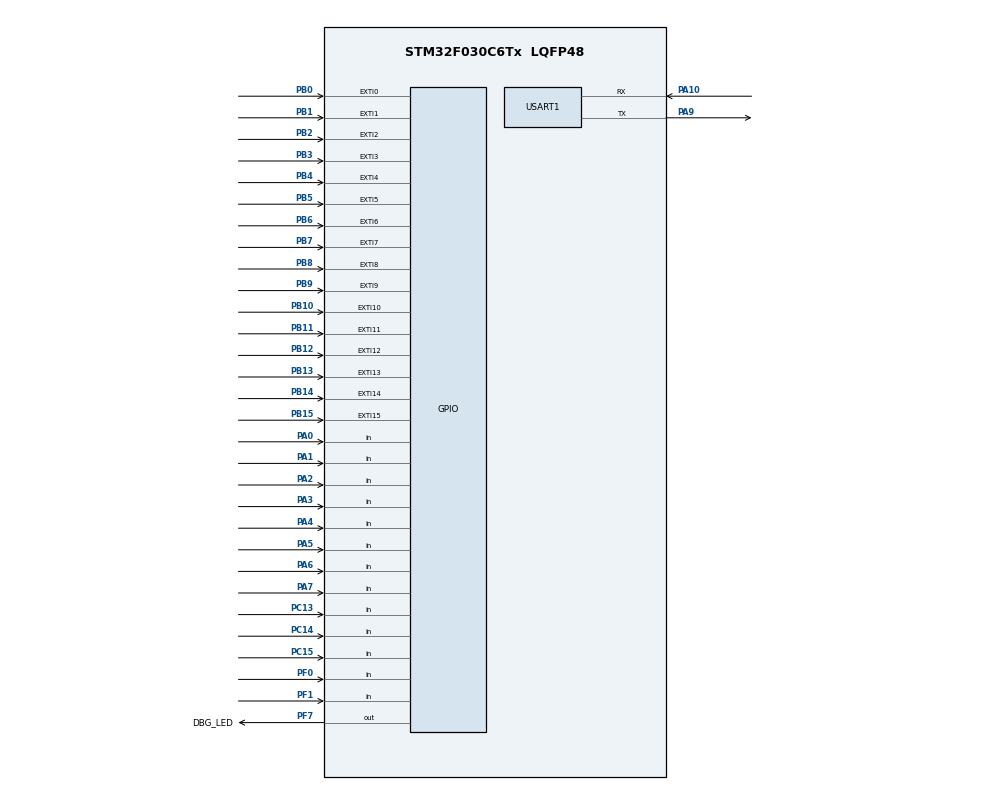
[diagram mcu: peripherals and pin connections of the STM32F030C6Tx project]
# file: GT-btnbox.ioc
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Mcu.Family=STM32F0
Mcu.Name=STM32F030C6Tx
Mcu.Package=LQFP48
NVIC.EXTI0_1_IRQn=true\:2\:0\:true\:true\:true\:1\:true
NVIC.EXTI2_3_IRQn=true\:2\:0\:true\:true\:true\:2\:true
NVIC.EXTI4_15_IRQn=true\:2\:0\:true\:true\:true\:3\:true
PA0.GPIO_PuPd=GPIO_PULLUP
PA0.Signal=GPIO_Input
PA1.GPIO_PuPd=GPIO_PULLUP
PA1.Signal=GPIO_Input
PA10.Mode=Asynchronous
PA10.Signal=USART1_RX
PA13.Mode=Serial_Wire
PA13.Signal=SYS_SWDIO
PA14.Mode=Serial_Wire
PA14.Signal=SYS_SWCLK
PA2.GPIO_PuPd=GPIO_PULLUP
PA2.Signal=GPIO_Input
PA3.GPIO_PuPd=GPIO_PULLUP
PA3.Signal=GPIO_Input
PA4.GPIO_PuPd=GPIO_PULLUP
PA4.Signal=GPIO_Input
PA5.GPIO_PuPd=GPIO_PULLUP
PA5.Signal=GPIO_Input
PA6.GPIO_PuPd=GPIO_PULLUP
PA6.Signal=GPIO_Input
PA7.GPIO_PuPd=GPIO_PULLUP
PA7.Signal=GPIO_Input
PA8.GPIO_Speed=GPIO_SPEED_FREQ_HIGH
PA8.Signal=S_TIM1_CH1
PA9.Mode=Asynchronous
PA9.Signal=USART1_TX
PB0.GPIO_PuPd=GPIO_PULLUP
PB0.Signal=GPXTI0
PB1.GPIO_PuPd=GPIO_PULLUP
PB1.Signal=GPXTI1
PB10.GPIO_PuPd=GPIO_PULLUP
PB10.Signal=GPXTI10
PB11.GPIO_PuPd=GPIO_PULLUP
PB11.Signal=GPXTI11
PB12.GPIO_PuPd=GPIO_PULLUP
PB12.Signal=GPXTI12
PB13.GPIO_PuPd=GPIO_PULLUP
PB13.Signal=GPXTI13
PB14.GPIO_PuPd=GPIO_PULLUP
PB14.Signal=GPXTI14
PB15.GPIO_PuPd=GPIO_PULLUP
PB15.Signal=GPXTI15
PB2.GPIO_PuPd=GPIO_PULLUP
PB2.Signal=GPXTI2
PB3.GPIO_PuPd=GPIO_PULLUP
PB3.Signal=GPXTI3
PB4.GPIO_PuPd=GPIO_PULLUP
PB4.Signal=GPXTI4
PB5.GPIO_PuPd=GPIO_PULLUP
PB5.Signal=GPXTI5
PB6.GPIO_PuPd=GPIO_PULLUP
PB6.Signal=GPXTI6
PB7.GPIO_PuPd=GPIO_PULLUP
PB7.Signal=GPXTI7
PB8.GPIO_PuPd=GPIO_PULLUP
PB8.Signal=GPXTI8
PB9.GPIO_PuPd=GPIO_PULLUP
PB9.Signal=GPXTI9
PC13.GPIO_PuPd=GPIO_PULLUP
PC13.Signal=GPIO_Input
PC14-OSC32_IN.GPIO_PuPd=GPIO_PULLUP
PC14-OSC32_IN.Signal=GPIO_Input
PC15-OSC32_OUT.GPIO_PuPd=GPIO_PULLUP
PC15-OSC32_OUT.Signal=GPIO_Input
PF0-OSC_IN.GPIO_PuPd=GPIO_PULLUP
PF0-OSC_IN.Signal=GPIO_Input
PF1-OSC_OUT.GPIO_PuPd=GPIO_PULLUP
PF1-OSC_OUT.Signal=GPIO_Input
PF7.GPIO_Label=DBG_LED
PF7.GPIO_PuPd=GPIO_NOPULL
PF7.Signal=GPIO_Output
ProjectManager.HeapSize=0x200
ProjectManager.StackSize=0x400
ProjectManager.TargetToolchain=MDK-ARM V5
SH.S_TIM1_CH1.0=TIM1_CH1
USART1.VirtualMode-Asynchronous=VM_ASYNC
board=custom

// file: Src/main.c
/**
  ******************************************************************************
  * @file           : main.c
  * @brief          : Main program body
  ******************************************************************************
  ** This notice applies to any and all portions of this file
  * that are not between comment pairs USER CODE BEGIN and
  * USER CODE END. Other portions of this file, whether
  * inserted by the user or by software development tools
  * are owned by their respective copyright owners.
  *
  * COPYRIGHT(c) 2018 STMicroelectronics
  *
  * Redistribution and use in source and binary forms, with or without modification,
  * are permitted provided that the following conditions are met:
  *   1. Redistributions of source code must retain the above copyright notice,
  *      this list of conditions and the following disclaimer.
  *   2. Redistributions in binary form must reproduce the above copyright notice,
  *      this list of conditions and the following disclaimer in the documentation
  *      and/or other materials provided with the distribution.
  *   3. Neither the name of STMicroelectronics nor the names of its contributors
  *      may be used to endorse or promote products derived from this software
  *      without specific prior written permission.
  *
  * THIS SOFTWARE IS PROVIDED BY THE COPYRIGHT HOLDERS AND CONTRIBUTORS "AS IS"
  * AND ANY EXPRESS OR IMPLIED WARRANTIES, INCLUDING, BUT NOT LIMITED TO, THE
  * IMPLIED WARRANTIES OF MERCHANTABILITY AND FITNESS FOR A PARTICULAR PURPOSE ARE
  * DISCLAIMED. IN NO EVENT SHALL THE COPYRIGHT HOLDER OR CONTRIBUTORS BE LIABLE
  * FOR ANY DIRECT, INDIRECT, INCIDENTAL, SPECIAL, EXEMPLARY, OR CONSEQUENTIAL
  * DAMAGES (INCLUDING, BUT NOT LIMITED TO, PROCUREMENT OF SUBSTITUTE GOODS OR
  * SERVICES; LOSS OF USE, DATA, OR PROFITS; OR BUSINESS INTERRUPTION) HOWEVER
  * CAUSED AND ON ANY THEORY OF LIABILITY, WHETHER IN CONTRACT, STRICT LIABILITY,
  * OR TORT (INCLUDING NEGLIGENCE OR OTHERWISE) ARISING IN ANY WAY OUT OF THE USE
  * OF THIS SOFTWARE, EVEN IF ADVISED OF THE POSSIBILITY OF SUCH DAMAGE.
  *
  ******************************************************************************
  */
#include "main.h"
#include "stm32f0xx_hal.h"
#include "usart.h"
#include "gpio.h"

/* USER CODE BEGIN PV */
/* Private variables ---------------------------------------------------------*/

/* USER CODE END PV */

void SystemClock_Config(void);
static void MX_NVIC_Init(void);

/* USER CODE BEGIN PFP */
/* Private function prototypes -----------------------------------------------*/

/* USER CODE END PFP */

/* USER CODE BEGIN 0 */

//http://www.rotr.info/electronics/mcu/stm32f100/stm32_exti.htm

/* USER CODE END 0 */

int main(void)
{

  /* MCU Configuration----------------------------------------------------------*/

  /* Reset of all peripherals, Initializes the Flash interface and the Systick. */
  HAL_Init();

  /* Configure the system clock */
  SystemClock_Config();

  /* Initialize all configured peripherals */
  MX_GPIO_Init();
  MX_USART1_UART_Init();

  /* Initialize interrupts */
  MX_NVIC_Init();
  /* USER CODE BEGIN 2 */

	HAL_NVIC_SetPriority(SysTick_IRQn, 0, 0);

  __WFI();
  __WFI();
  //LL_LPM_EnableSleep();

  /* USER CODE END 2 */

  /* Infinite loop */
  /* USER CODE BEGIN WHILE */
  while (1)
  {
		//Test
		/*
		HAL_Delay(500);
		HAL_GPIO_WritePin(DbgLed_GPIO_Port, DBG_LED, GPIO_PIN_SET);
		HAL_Delay(500);
		HAL_GPIO_WritePin(DbgLed_GPIO_Port, DBG_LED, GPIO_PIN_RESET);
		*/
  /* USER CODE END WHILE */

  }

}

void SystemClock_Config(void)
{

  RCC_OscInitTypeDef RCC_OscInitStruct;
  RCC_ClkInitTypeDef RCC_ClkInitStruct;
  RCC_PeriphCLKInitTypeDef PeriphClkInit;

    /**Initializes the CPU, AHB and APB busses clocks
    */
  RCC_OscInitStruct.OscillatorType = RCC_OSCILLATORTYPE_HSI;
  RCC_OscInitStruct.HSIState = RCC_HSI_ON;
  RCC_OscInitStruct.HSICalibrationValue = 16;
  RCC_OscInitStruct.PLL.PLLState = RCC_PLL_NONE;
  if (HAL_RCC_OscConfig(&RCC_OscInitStruct) != HAL_OK)
  {
    _Error_Handler(__FILE__, __LINE__);
  }

    /**Initializes the CPU, AHB and APB busses clocks
    */
  RCC_ClkInitStruct.ClockType = RCC_CLOCKTYPE_HCLK|RCC_CLOCKTYPE_SYSCLK
                              |RCC_CLOCKTYPE_PCLK1;
  RCC_ClkInitStruct.SYSCLKSource = RCC_SYSCLKSOURCE_HSI;
  RCC_ClkInitStruct.AHBCLKDivider = RCC_SYSCLK_DIV1;
  RCC_ClkInitStruct.APB1CLKDivider = RCC_HCLK_DIV1;

  if (HAL_RCC_ClockConfig(&RCC_ClkInitStruct, FLASH_LATENCY_0) != HAL_OK)
  {
    _Error_Handler(__FILE__, __LINE__);
  }

  PeriphClkInit.PeriphClockSelection = RCC_PERIPHCLK_USART1;
  PeriphClkInit.Usart1ClockSelection = RCC_USART1CLKSOURCE_PCLK1;
  if (HAL_RCCEx_PeriphCLKConfig(&PeriphClkInit) != HAL_OK)
  {
    _Error_Handler(__FILE__, __LINE__);
  }

    /**Configure the Systick interrupt time
    */
  HAL_SYSTICK_Config(HAL_RCC_GetHCLKFreq()/1000);

    /**Configure the Systick
    */
  HAL_SYSTICK_CLKSourceConfig(SYSTICK_CLKSOURCE_HCLK);

  /* SysTick_IRQn interrupt configuration */
  HAL_NVIC_SetPriority(SysTick_IRQn, 0, 0);
}

/**
  * @brief NVIC Configuration.
  * @retval None
  */
static void MX_NVIC_Init(void)
{
  /* EXTI0_1_IRQn interrupt configuration */
  HAL_NVIC_SetPriority(EXTI0_1_IRQn, 2, 0);
  HAL_NVIC_EnableIRQ(EXTI0_1_IRQn);
  /* EXTI2_3_IRQn interrupt configuration */
  HAL_NVIC_SetPriority(EXTI2_3_IRQn, 2, 0);
  HAL_NVIC_EnableIRQ(EXTI2_3_IRQn);
  /* EXTI4_15_IRQn interrupt configuration */
  HAL_NVIC_SetPriority(EXTI4_15_IRQn, 2, 0);
  HAL_NVIC_EnableIRQ(EXTI4_15_IRQn);
}

/* USER CODE BEGIN 4 */
void HAL_GPIO_EXTI_Callback(uint16_t GPIO_Pin)
{
	HAL_GPIO_TogglePin(GPIOF, DBG_LED_Pin);
}

/* USER CODE END 4 */

void _Error_Handler(char *file, int line)
{
  while(1)
  {
  }
}

/************************ (C) COPYRIGHT STMicroelectronics *****END OF FILE****/
